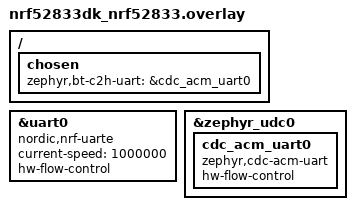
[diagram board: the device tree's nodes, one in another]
/*
 * Copyright (c) 2022 Nordic Semiconductor ASA
 *
 * SPDX-License-Identifier: Apache-2.0
 */

 &uart0 {
	compatible = "nordic,nrf-uarte";
	current-speed = <1000000>;
	status = "okay";
	hw-flow-control;
};

&zephyr_udc0 {
	cdc_acm_uart0: cdc_acm_uart0 {
		compatible = "zephyr,cdc-acm-uart";
		hw-flow-control;
	};
};
/{
	chosen {
		zephyr,bt-c2h-uart = &cdc_acm_uart0;
	};
};
